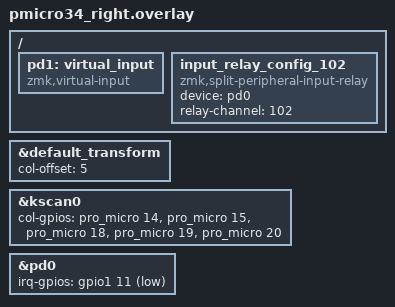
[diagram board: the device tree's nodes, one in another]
/*
 * Copyright (c) 2020 Pete Johanson
 *
 * SPDX-License-Identifier: MIT
 */

#include "pmicro34.dtsi"

&default_transform {
	col-offset = <5>;
};

&kscan0 {
	col-gpios
		= <&pro_micro 14 GPIO_ACTIVE_HIGH>
		, <&pro_micro 15 GPIO_ACTIVE_HIGH>
		, <&pro_micro 18 GPIO_ACTIVE_HIGH>
		, <&pro_micro 19 GPIO_ACTIVE_HIGH>
		, <&pro_micro 20 GPIO_ACTIVE_HIGH>
		;
};

#include "pmicro34_trackball.dtsi"

/* enable &pd0 on split peripheral. typical input device for zephyr input subsystem. */
/* NOTE 1: use the same device alias (&pd0) on central and peripheral(s) is alright. */
/* NOTE 2: input event shall be intecepted by module `zmk-split-peripheral-input-relay`. */
&pd0 {
  status = "okay";
  irq-gpios = <&gpio1 11 (GPIO_ACTIVE_LOW | GPIO_PULL_UP)>;
};

/ {
	/* THIS make keymap binding happy only, nothing happen on peripheral side */
	pd1: virtual_input {
		compatible = "zmk,virtual-input";
	};
};

/ {
	/* for peripheral side, define (input-device)-to-(relay-channel) mapping */
	input_relay_config_102 {
		compatible = "zmk,split-peripheral-input-relay";

		/* peripheral side input device, used to be intecepted and be resurrected on central */
		device = <&pd0>;
		
		/* channel id, used to annotate raw input event */
		/* NOTE: should matching relay-channel on central overlay */
		relay-channel = <102>;
	};
};

// / {
// 	lra0: haptic_generic_lra {
// 		compatible = "zmk,haptic-generic";
// 		#haptic-binding-cells = <0>;
// 		control-gpios = <&gpio0 5 GPIO_ACTIVE_HIGH>;
// 	};
// };
